VERSION ""

NS_ :

BS_:

BU_: EON EON 75 half EON 9C-BC EON  75 half EON   9C-BC XXX

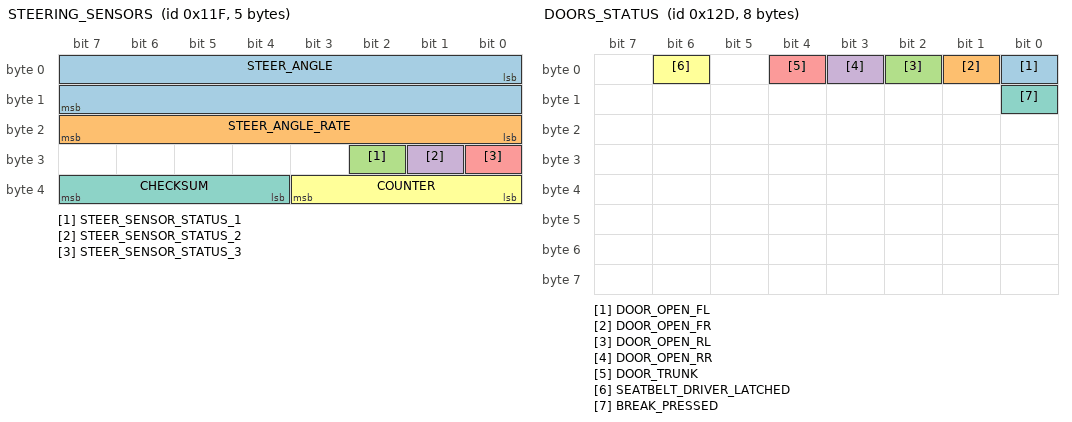
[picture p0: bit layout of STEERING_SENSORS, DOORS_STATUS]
BO_ 287 STEERING_SENSORS: 5 EPS
 SG_ STEER_ANGLE : 0|16@1- (0.1,0) [-650|650] "deg" EON
 SG_ STEER_ANGLE_RATE : 16|8@1- (0.1,0) [-3000|3000] "deg/s" EON
 SG_ STEER_SENSOR_STATUS_1 : 26|1@0+ (1,0) [0|1] "" EON
 SG_ STEER_SENSOR_STATUS_2 : 25|1@0+ (1,0) [0|1] "" EON
 SG_ STEER_SENSOR_STATUS_3 : 24|1@0+ (1,0) [0|1] "" EON
 SG_ COUNTER : 32|4@1+ (1,0) [0|255] "" EON
 SG_ CHECKSUM : 36|4@1+ (1,0) [0|255] "" EON

BO_ 523 LIGHT: 8 BDY
 SG_ LIGHT : 24|4@1+ (1,0) [0|16] "" EON

BO_ 301 DOORS_STATUS: 8 BDY
 SG_ DOOR_OPEN_FL : 0|1@0+ (1,0) [0|1] "" EON
 SG_ DOOR_OPEN_FR : 1|1@0+ (1,0) [0|1] "" EON
 SG_ DOOR_OPEN_RL : 2|1@0+ (1,0) [0|1] "" EON
 SG_ DOOR_OPEN_RR : 3|1@0+ (1,0) [0|1] "" EON
 SG_ DOOR_TRUNK : 4|1@0+ (1,0) [0|1] "" EON
 SG_ SEATBELT_DRIVER_LATCHED : 6|1@0+ (1,0) [0|1] "" EON
 SG_ BREAK_PRESSED : 8|1@0+ (1,0) [0|1] "" EON

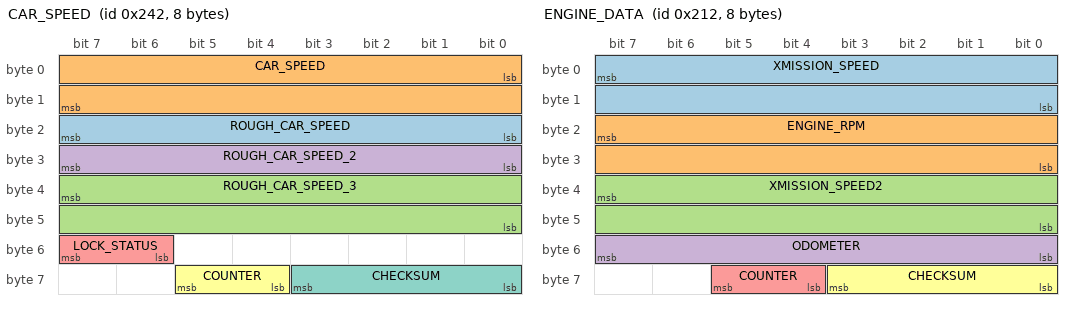
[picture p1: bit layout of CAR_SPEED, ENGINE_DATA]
BO_ 578 CAR_SPEED: 8 PCM
 SG_ ROUGH_CAR_SPEED : 23|8@0+ (1,0) [0|255] "mph" XXX
 SG_ CAR_SPEED : 0|16@1+ (0.017,-510) [0|255] "" EON
 SG_ ROUGH_CAR_SPEED_3 : 39|16@0+ (0.01,0) [0|65535] "kph" XXX
 SG_ ROUGH_CAR_SPEED_2 : 31|8@0+ (1,0) [0|255] "mph" XXX
 SG_ LOCK_STATUS : 55|2@0+ (1,0) [0|255] "" XXX
 SG_ COUNTER : 61|2@0+ (1,0) [0|3] "" XXX
 SG_ CHECKSUM : 59|4@0+ (1,0) [0|15] "" XXX

BO_ 530 ENGINE_DATA: 8 PCM
 SG_ XMISSION_SPEED : 7|16@0+ (0.01,0) [0|250] "kph" EON
 SG_ ENGINE_RPM : 23|16@0+ (1,0) [0|15000] "rpm" EON
 SG_ XMISSION_SPEED2 : 39|16@0+ (0.01,0) [0|250] "kph" EON
 SG_ ODOMETER : 55|8@0+ (10,0) [0|2550] "m" XXX
 SG_ COUNTER : 61|2@0+ (1,0) [0|3] "" EON
 SG_ CHECKSUM : 59|4@0+ (1,0) [0|15] "" EON

BO_ 290 POWERTRAIN_DATA: 8 PCM
 SG_ PEDAL_GAS : 7|8@0+ (1,0) [0|255] "" EON
 SG_ ENGINE_RPM : 23|16@0+ (1,0) [0|15000] "rpm" EON
 SG_ GAS_PRESSED : 39|1@0+ (1,0) [0|1] "" EON
 SG_ ACC_STATUS : 38|1@0+ (1,0) [0|1] "" EON
 SG_ BOH_17C : 37|5@0+ (1,0) [0|1] "" EON
 SG_ BRAKE_SWITCH : 32|1@0+ (1,0) [0|1] "" EON
 SG_ BOH2_17C : 47|10@0+ (1,0) [0|1] "" EON
 SG_ BRAKE_PRESSED : 53|1@0+ (1,0) [0|1] "" EON
 SG_ BOH3_17C : 52|5@0+ (1,0) [0|1] "" EON
 SG_ COUNTER : 61|2@0+ (1,0) [0|3] "" EON
 SG_ CHECKSUM : 59|4@0+ (1,0) [0|15] "" EON

BO_ 834 GAS_POSITION: 8 BDY
 SG_ GAS_P1 : 7|8@0+ (1,0) [0|255] "" EON
 SG_ ECO_SPORT : 20|4@1+ (1,0) [0|255] "" EON
 SG_ EV_HEV : 28|4@1+ (1,0) [0|255] "" EON

BO_ 548 BREAK_POSITION: 8 BDY
 SG_ BREAK_P4 : 32|16@1+ (1,0) [0|255] "" EON   9C-BC

BO_ 549 BREAK_POSITION2: 8 BDY
 SG_ BREAK_P5 : 24|16@1+ (1,0) [0|255] "" EON

BO_ 860 GEARBOX: 8 PCM
 SG_ GEAR_SHIFTER : 5|6@0+ (1,0) [0|63] "" EON
 SG_ BOH : 45|6@0+ (1,0) [0|63] "" XXX
 SG_ GEAR2 : 31|8@0+ (1,0) [0|1] "" XXX
 SG_ GEAR : 39|8@0+ (1,0) [0|255] "" XXX
 SG_ ZEROS_BOH : 47|2@0+ (1,0) [0|3] "" XXX
 SG_ COUNTER : 61|2@0+ (1,0) [0|3] "" EON
 SG_ CHECKSUM : 59|4@0+ (1,0) [0|15] "" EON

BO_ 665 STEERING_KEY: 8 EPS
 SG_ STEER_KEY : 20|4@1- (1,0) [0|255] "" EON

BO_ 291 NEW_MSG_1: 8 XXX

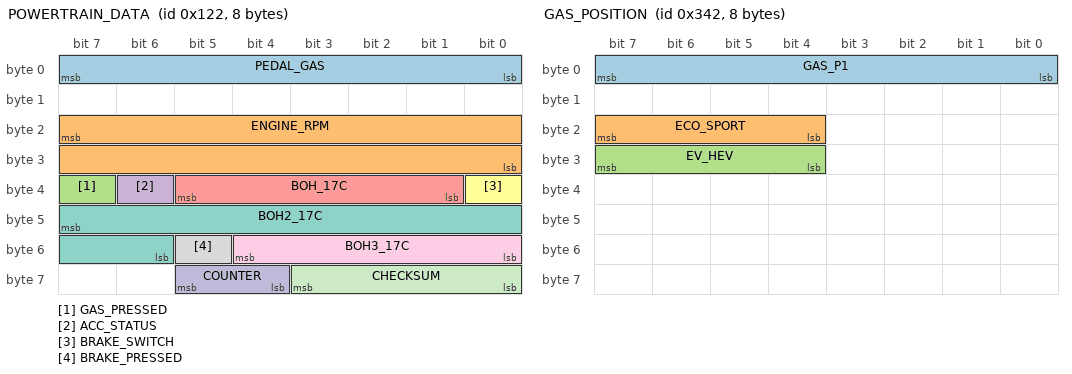
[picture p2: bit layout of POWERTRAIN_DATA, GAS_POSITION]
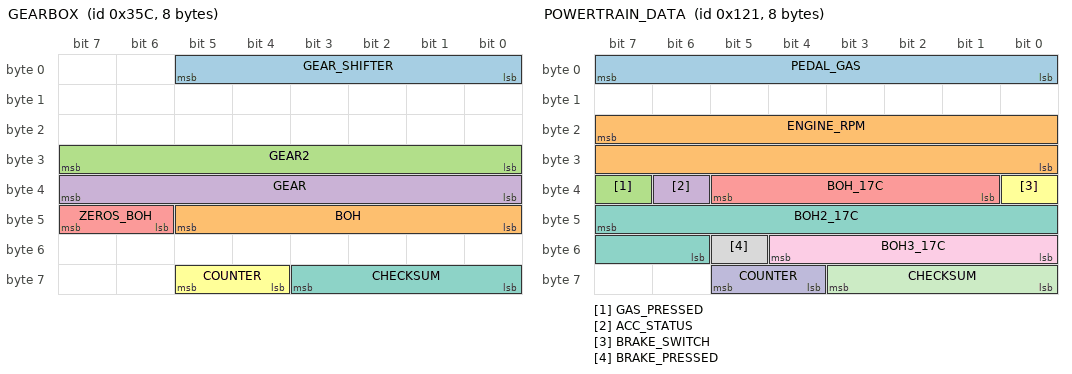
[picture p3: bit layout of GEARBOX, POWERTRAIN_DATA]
BO_ 289 POWERTRAIN_DATA: 8 PCM
 SG_ PEDAL_GAS : 7|8@0+ (1,0) [0|255] "" EON
 SG_ ENGINE_RPM : 23|16@0+ (1,0) [0|15000] "rpm" EON
 SG_ GAS_PRESSED : 39|1@0+ (1,0) [0|1] "" EON
 SG_ ACC_STATUS : 38|1@0+ (1,0) [0|1] "" EON
 SG_ BOH_17C : 37|5@0+ (1,0) [0|1] "" EON
 SG_ BRAKE_SWITCH : 32|1@0+ (1,0) [0|1] "" EON
 SG_ BOH2_17C : 47|10@0+ (1,0) [0|1] "" EON
 SG_ BRAKE_PRESSED : 53|1@0+ (1,0) [0|1] "" EON
 SG_ BOH3_17C : 52|5@0+ (1,0) [0|1] "" EON
 SG_ COUNTER : 61|2@0+ (1,0) [0|3] "" EON
 SG_ CHECKSUM : 59|4@0+ (1,0) [0|15] "" EON

BO_ 290 NEW_MSG_2: 8 XXX
 SG_ NEW_SIGNAL_1 : 23|8@0- (1,0) [0|255] "" XXX

VAL_ 523 LIGHT 15 "OFF" 12 "AUTO" 9 "AUTO" 7 "NIGHT" 6 "LONG" 4 "LONG" 5 "LONG" ;
VAL_ 530 GEAR 4 "D" 3 "N" 2 "R" 1 "P" ;
VAL_ 530 BREAK_P2 8 "release" 12 "press" ;
VAL_ 269 BREAK_P3 67 "release" 71 "press" 75 "half" ;
VAL_ 834 ECO_SPORT 2 "sport" 1 "eco" ;
VAL_ 834 EV_HEV 9 "EV" 11 "HEV" ;
VAL_ 860 GEAR2 4 "D" 3 "N" 2 "R" 1 "P" ;
